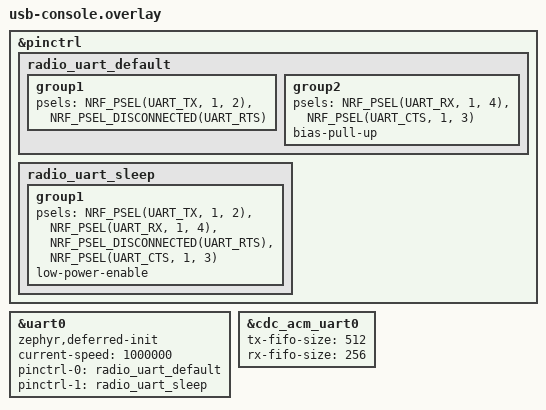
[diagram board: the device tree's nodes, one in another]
#include <zephyr/dt-bindings/pinctrl/nrf-pinctrl.h>
&pinctrl {
 radio_uart_default: radio_uart_default {
  group1 { psels = <NRF_PSEL(UART_TX, 1, 2)>, <NRF_PSEL_DISCONNECTED(UART_RTS)>; };
  group2 { psels = <NRF_PSEL(UART_RX, 1, 4)>, <NRF_PSEL(UART_CTS, 1, 3)>; bias-pull-up; };
 };
 radio_uart_sleep: radio_uart_sleep {
  group1 { psels = <NRF_PSEL(UART_TX, 1, 2)>, <NRF_PSEL(UART_RX, 1, 4)>,
                  <NRF_PSEL_DISCONNECTED(UART_RTS)>, <NRF_PSEL(UART_CTS, 1, 3)>;
           low-power-enable; };
 };
};
&uart0 {
 status = "okay";
 zephyr,deferred-init;
 current-speed = <1000000>;
 /delete-property/ hw-flow-control; /* BTID7: same query, without CTS gating. */
 pinctrl-0 = <&radio_uart_default>;
 pinctrl-1 = <&radio_uart_sleep>;
 pinctrl-names = "default", "sleep";
};

&cdc_acm_uart0 { tx-fifo-size = <512>; rx-fifo-size = <256>; };
